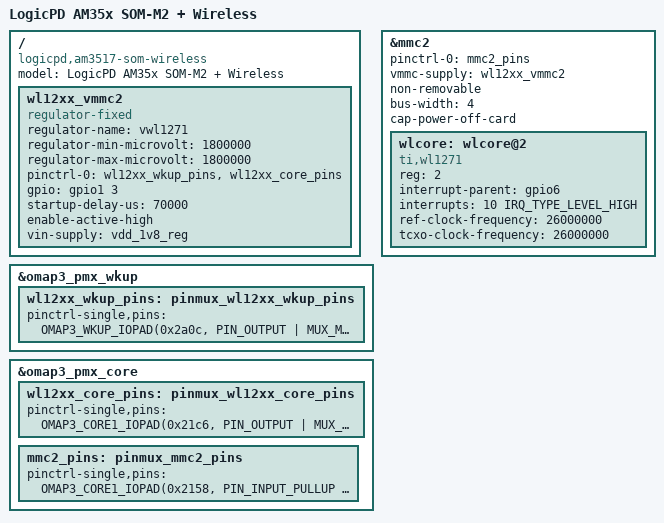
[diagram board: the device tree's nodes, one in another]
/*
 * Copyright (C) 2016 Derald D. Woods <woods.technical@gmail.com>
 *
 * This program is free software; you can redistribute it and/or modify
 * it under the terms of the GNU General Public License version 2 as
 * published by the Free Software Foundation.
 */

#include "logicpd-am3517-common.dtsi"

/ {
	model = "LogicPD AM35x SOM-M2 + Wireless";
	compatible = "logicpd,am3517-som-wireless", "ti,am3517", "ti,omap3";

	wl12xx_vmmc2: wl12xx_vmmc2 {
		compatible = "regulator-fixed";
		regulator-name = "vwl1271";
		regulator-min-microvolt = <1800000>;
		regulator-max-microvolt = <1800000>;
		pinctrl-names = "default";
		pinctrl-0 = <&wl12xx_wkup_pins &wl12xx_core_pins>;
		gpio = <&gpio1 3 GPIO_ACTIVE_HIGH >; /* gpio 3 */
		startup-delay-us = <70000>;
		enable-active-high;
		vin-supply = <&vdd_1v8_reg>;
	};
};

&omap3_pmx_wkup {

	wl12xx_wkup_pins: pinmux_wl12xx_wkup_pins {
		pinctrl-single,pins = <
			OMAP3_WKUP_IOPAD(0x2a0c, PIN_OUTPUT | MUX_MODE4)	/* sys_boot1.gpio_3 */
		>;
	};
};

&omap3_pmx_core {

	wl12xx_core_pins: pinmux_wl12xx_core_pins {
		pinctrl-single,pins = <
			OMAP3_CORE1_IOPAD(0x21c6, PIN_OUTPUT | MUX_MODE4)	/* hdq_sio.gpio_170 */
		>;
	};

	mmc2_pins: pinmux_mmc2_pins {
		pinctrl-single,pins = <
			OMAP3_CORE1_IOPAD(0x2158, PIN_INPUT_PULLUP | MUX_MODE0)  /* sdmmc2_clk.sdmmc2_clk */
			OMAP3_CORE1_IOPAD(0x215a, PIN_INPUT_PULLUP | MUX_MODE0)  /* sdmmc2_cmd.sdmmc2_cmd */
			OMAP3_CORE1_IOPAD(0x215c, PIN_INPUT_PULLUP | MUX_MODE0)  /* sdmmc2_dat0.sdmmc2_dat0 */
			OMAP3_CORE1_IOPAD(0x215e, PIN_INPUT_PULLUP | MUX_MODE0)  /* sdmmc2_dat1.sdmmc2_dat1 */
			OMAP3_CORE1_IOPAD(0x2160, PIN_INPUT_PULLUP | MUX_MODE0)  /* sdmmc2_dat2.sdmmc2_dat2 */
			OMAP3_CORE1_IOPAD(0x2162, PIN_INPUT_PULLUP | MUX_MODE0)  /* sdmmc2_dat3.sdmmc2_dat3 */
			OMAP3_CORE1_IOPAD(0x2164, PIN_OUTPUT_PULLUP | MUX_MODE1) /* sdmmc2_dat4.sdmmc2_dir_dat0 */
			OMAP3_CORE1_IOPAD(0x2166, PIN_OUTPUT_PULLUP | MUX_MODE1) /* sdmmc2_dat5.sdmmc2_dir_dat1 */
			OMAP3_CORE1_IOPAD(0x2168, PIN_OUTPUT_PULLUP | MUX_MODE1) /* sdmmc2_dat6.sdmmc2_dir_cmd */
			OMAP3_CORE1_IOPAD(0x216a, PIN_OUTPUT_PULLUP | MUX_MODE1) /* sdmmc2_dat7.sdmmc2_dir_clkin */
		>;
	};
};

&mmc2 {
	status = "okay";

	pinctrl-names = "default";
	pinctrl-0 = <&mmc2_pins>;
	vmmc-supply = <&wl12xx_vmmc2>;
	non-removable;
	bus-width = <4>;
	cap-power-off-card;
	#address-cells = <1>;
	#size-cells = <0>;
	wlcore: wlcore@2 {
		compatible = "ti,wl1271";
		reg = <2>;
		interrupt-parent = <&gpio6>;
		interrupts = <10 IRQ_TYPE_LEVEL_HIGH>; /* gpio 170 */
		ref-clock-frequency = <26000000>;
		tcxo-clock-frequency = <26000000>;
	};
};
